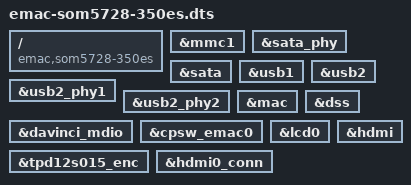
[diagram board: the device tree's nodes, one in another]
/*
 * Copyright (C) 2014-2016 Texas Instruments Incorporated - http://www.ti.com/
 *
 * This program is free software; you can redistribute it and/or modify
 * it under the terms of the GNU General Public License version 2 as
 * published by the Free Software Foundation.
 */
/dts-v1/;

#include "emac-som5728.dtsi"

/ {
	compatible = "emac,som5728-350es", "emac,som5728", "ti,am5728", "ti,dra742", "ti,dra74", "ti,dra7";
};

// SD Card
&mmc1 {
    status = "okay";
};

// Enable SATA
&sata_phy {
	status = "okay";
};
&sata {
	status = "okay";
};

// usb3.x interface
&usb1 { 
	status = "okay";
};
&usb2_phy1 {
	status = "okay";
};

// usb2.x interface
&usb2 { 
	status = "okay";
};
&usb2_phy2 {
	status = "okay";
};

&mac{
	status = "okay";
};

&davinci_mdio {
    status = "okay";
};

&cpsw_emac0 {
    status = "okay";
};


// Display info
&dss {
	status = "okay";
};
&lcd0 {
	status = "okay";
};
&hdmi {
	status = "okay";
};
&tpd12s015_enc {
	status = "okay";
};
&hdmi0_conn {
	status = "okay";
};







